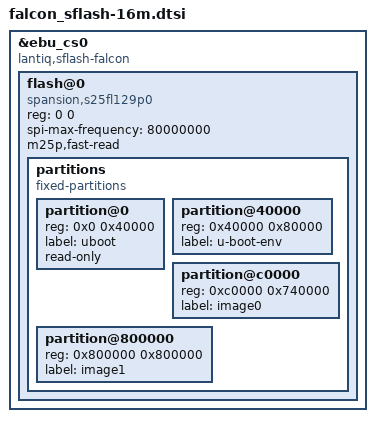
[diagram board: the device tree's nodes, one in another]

&ebu_cs0 {
	#address-cells = <1>;
	#size-cells = <1>;
	compatible = "lantiq,sflash-falcon", "simple-bus";

	flash@0 {
		compatible = "spansion,s25fl129p0", "spansion,s25fl129p1";
		reg = <0 0>;
		spi-max-frequency = <80000000>;
		m25p,fast-read;

		partitions {
			compatible = "fixed-partitions";
			#address-cells = <1>;
			#size-cells = <1>;

			partition@0 {
				reg = <0x0 0x40000>;
				label = "uboot";
				read-only;
			};

			partition@40000 {
				reg = <0x40000 0x80000>;
				label = "u-boot-env";
			};

			partition@c0000 {
				reg = <0xc0000 0x740000>;
				label = "image0";
			};

			partition@800000 {
				reg = <0x800000 0x800000>;
				label = "image1";
			};
		};
	};
};
